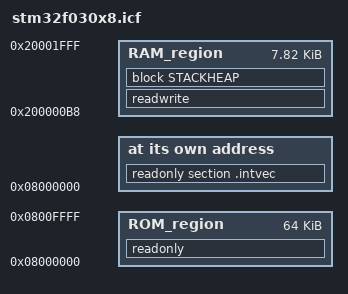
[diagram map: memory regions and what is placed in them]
/* [ROM = 64kb = 0x10000] */
define symbol __intvec_start__     = 0x08000000;
define symbol __region_ROM_start__ = 0x08000000;
define symbol __region_ROM_end__   = 0x0800FFFF;

/* [RAM = 8kb = 0x2000] Vector table dynamic copy: 45 vectors = 180 bytes (0xB4) to be reserved in RAM */
define symbol __NVIC_start__          = 0x20000000;
define symbol __NVIC_end__            = 0x200000B7; /* Add 4 more bytes to be aligned on 8 bytes */
define symbol __region_RAM_start__    = 0x200000B8;
define symbol __region_RAM_end__      = 0x20001FFF;

/* Memory regions */
define memory mem with size = 4G;
define region ROM_region = mem:[from __region_ROM_start__ to __region_ROM_end__];
define region RAM_region = mem:[from __region_RAM_start__ to __region_RAM_end__];

/* Stack and Heap */
/*Heap 1/4 of ram and stack 1/8*/
define symbol __size_cstack__ = 0x400;
define symbol __size_heap__   = 0x800;
define block CSTACK    with alignment = 8, size = __size_cstack__   { };
define block HEAP      with alignment = 8, size = __size_heap__     { };
define block STACKHEAP with fixed order { block HEAP, block CSTACK };

initialize by copy with packing = zeros { readwrite };
do not initialize  { section .noinit };

place at address mem:__intvec_start__ { readonly section .intvec };

place in ROM_region   { readonly };
place in RAM_region   { readwrite, block STACKHEAP };
